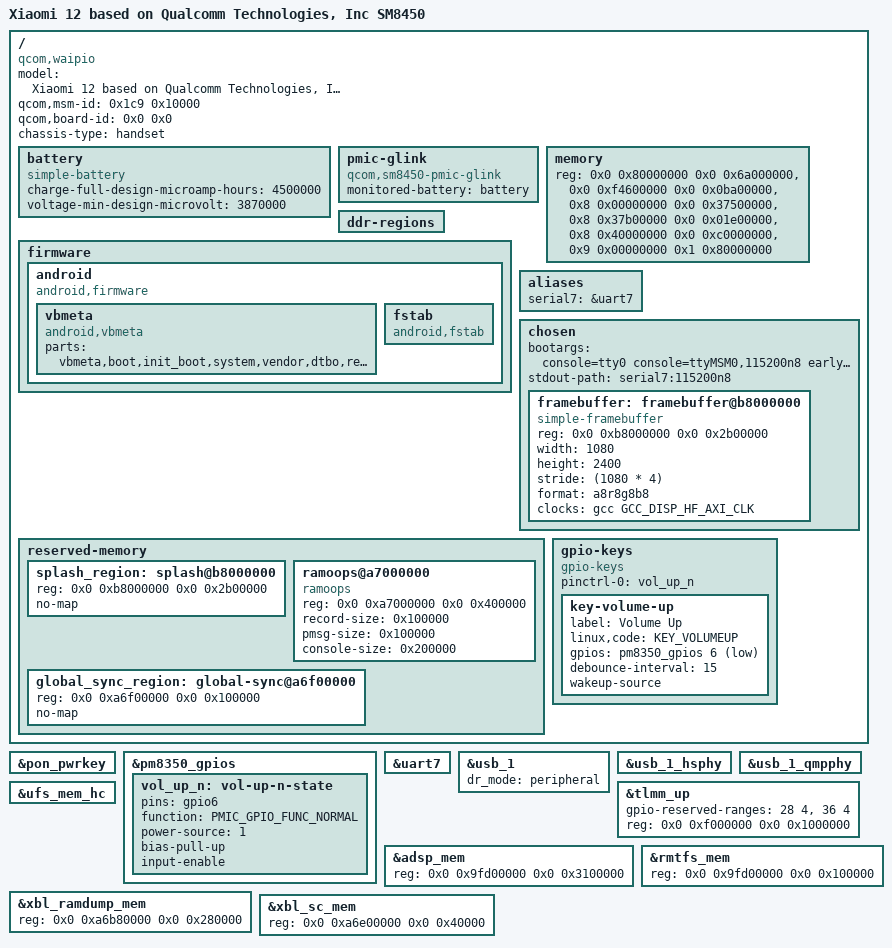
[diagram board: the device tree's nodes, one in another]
// SPDX-License-Identifier: GPL-2.0-only
/*
 * Board device tree for Xiaomi 12 (cupid) — Qualcomm SM8450 (Snapdragon 8 Gen 1).
 *
 * All values from on-device forensics (2026-10-27):
 *   - runtime device tree (private/device-tree.tar, kernel 5.10.237 vendor build)
 *   - /proc/cmdline, fastboot getvar all, panel modes
 * Reference template: sm8475-xiaomi-marble.dts (same-generation Xiaomi port).
 *
 * Minimal boot set (android-mainline-port step 3): console, USB device mode,
 * UFS, keys, ramoops, borrowed firmware framebuffer. Peripherals (panel
 * native takeover, touch, audio, Wi-Fi) follow in later steps.
 */
/dts-v1/;

#include <dt-bindings/arm/qcom,ids.h>
#include <dt-bindings/gpio/gpio.h>
#include <dt-bindings/input/input.h>
#include <dt-bindings/pinctrl/qcom,pmic-gpio.h>
#include <dt-bindings/regulator/qcom,rpmh-regulator.h>

#include "sm8450.dtsi"
#include "pm8350.dtsi"
#include "pm8350b.dtsi"
#include "pm8350c.dtsi"
#include "pm8450.dtsi"
#include "pmk8350.dtsi"
#include "pmr735a.dtsi"
#include "sm8450-xiaomi-cupid-syms.dtsi"

/*
 * XBL allocates firmware carve-outs per device. The SoC dtsi placeholders
 * for adsp/xbl_ramdump/xbl_sc do not match this unit (forensics:
 * adsp@9fd00000, xbl_ramdump@a6b80000, xbl-sc@a6e00000) and are overridden
 * by label at the end of this file. mpss_mem@8bc00000 already matches.
 */

/ {
	model = "Xiaomi 12 based on Qualcomm Technologies, Inc SM8450";
	compatible = "qcom,waipio", "xiaomi,cupid", "qcom,sm8450";
	/*
	 * ABL picks the matching DTB out of the vendor_boot multi-DTB
	 * container by qcom,msm-id + qcom,board-id.
	 *
	 * SM8450 is Waipio: the stock container's waipio entry carries
	 * msm-id <0x1c9 0x10000>, board-id <0 0>. (Entry 0 of the same
	 * container is cape-v2 = SM8475, a different SoC — do not copy it.)
	 * The values in the runtime /sys/firmware/fdt (<201 0 226 0>) are
	 * what the dtbo overlay wrote over the root afterwards.
	 */
	qcom,msm-id = <0x1c9 0x10000>;
	qcom,board-id = <0x0 0x0>;
	chassis-type = "handset";

	/*
	 * Battery/charger run in ADSP firmware (battmgr) over pmic_glink.
	 * 4500 mAh cell (spec); design voltage assumed — verify on device.
	 */
	battery: battery {
		compatible = "simple-battery";
		charge-full-design-microamp-hours = <4500000>;
		voltage-min-design-microvolt = <3870000>;
	};

	pmic-glink {
		compatible = "qcom,sm8450-pmic-glink", "qcom,pmic-glink";
		#address-cells = <1>;
		#size-cells = <0>;
		monitored-battery = <&battery>;
	};

	/delete-node/ memory@a0000000;

	/*
	 * 12 GiB LPDDR5, six physical banks from the runtime DT + Android
	 * /proc/iomem System RAM. The stock base DTB leaves /memory empty for
	 * ABL to fill, but ABL does not fill OUR tree (it only patches the
	 * shape it shipped) — leaving reg empty here means the kernel starts
	 * with zero memory and panics before it can print anything.
	 */
	memory {
		device_type = "memory";
		reg = <0x0 0x80000000 0x0 0x6a000000>,
		      <0x0 0xf4600000 0x0 0x0ba00000>,
		      <0x8 0x00000000 0x0 0x37500000>,
		      <0x8 0x37b00000 0x0 0x01e00000>,
		      <0x8 0x40000000 0x0 0xc0000000>,
		      <0x9 0x00000000 0x1 0x80000000>;
	};

	ddr-regions {
	};

	/* Stock base DTB carries these; keep the same shape for the ABL. */
	firmware {
		android {
			compatible = "android,firmware";

			vbmeta {
				compatible = "android,vbmeta";
				parts = "vbmeta,boot,init_boot,system,vendor,dtbo,recovery";
			};

			fstab {
				compatible = "android,fstab";
			};
		};
	};

	aliases {
		serial7 = &uart7;
	};

	chosen {
		/*
		 * ABL reads /chosen/bootargs from the device tree (not just the
		 * boot.img header) and appends its own args. Keep it short — the
		 * bootloader's buffer is ~512 bytes and silently truncates.
		 */
		bootargs = "console=tty0 console=ttyMSM0,115200n8 earlycon loglevel=8 ignore_loglevel panic=10";
		stdout-path = "serial7:115200n8";

		/*
		 * Borrowed firmware display (splash_region, forensics: 0xb8000000
		 * 43 MiB, 1080x2400). First-boot only; native takeover in step 4.
		 * Panel: qcom,mdss_dsi_l3_42_02_0a_dsc_cmd (SeeYA OLED).
		 */
		framebuffer: framebuffer@b8000000 {
			compatible = "simple-framebuffer";
			reg = <0x0 0xb8000000 0x0 0x2b00000>;
			width = <1080>;
			height = <2400>;
			stride = <(1080 * 4)>;
			format = "a8r8g8b8";
			/* keep the display AXI clock alive — without it writes to
			 * the borrowed framebuffer do not reach the panel */
			clocks = <&gcc GCC_DISP_HF_AXI_CLK>;
		};
	};

	reserved-memory {
		splash_region: splash@b8000000 {
			reg = <0x0 0xb8000000 0x0 0x2b00000>;
			no-map;
		};

		ramoops@a7000000 {
			compatible = "ramoops";
			reg = <0x0 0xa7000000 0x0 0x400000>;
			record-size = <0x100000>;
			pmsg-size = <0x100000>;
			console-size = <0x200000>;
		};

		global_sync_region: global-sync@a6f00000 {
			reg = <0x0 0xa6f00000 0x0 0x100000>;
			no-map;
		};

		/* TODO(step 6 remotes): slpi@88000000/cdsp@89900000 placeholders
		 * already match this unit; add adsp_heap/audio_cma/spss/spu/va_md/
		 * camera/video/cvp/demura when those subsystems are enabled. */
	};

	gpio-keys {
		compatible = "gpio-keys";
		pinctrl-0 = <&vol_up_n>;
		pinctrl-names = "default";

		key-volume-up {
			label = "Volume Up";
			linux,code = <KEY_VOLUMEUP>;
			/* forensics: pm8350@1 pinctrl key_vol_up; gpio6 per
			 * marble reference — verify pins in key_vol_up_default */
			gpios = <&pm8350_gpios 6 GPIO_ACTIVE_LOW>;
			debounce-interval = <15>;
			wakeup-source;
		};
	};
};

&pon_pwrkey {
	status = "okay";
};

&pm8350_gpios {
	vol_up_n: vol-up-n-state {
		pins = "gpio6";
		function = PMIC_GPIO_FUNC_NORMAL;
		power-source = <1>;
		bias-pull-up;
		input-enable;
	};
};

&uart7 {
	status = "okay";
};

&usb_1 {
	status = "okay";
	/* netboot phase: device mode for USB NCM debug link.
	 * sm8450.dtsi merges the dwc3 core into usb_1 itself. */
	dr_mode = "peripheral";
};

/* Both PHYs are disabled in sm8450.dtsi — without them the dwc3
 * controller defers forever and no UDC appears for the gadget. */
&usb_1_hsphy {
	status = "okay";
};

&usb_1_qmpphy {
	status = "okay";
};

&ufs_mem_hc {
	status = "okay";
};

/*
 * GPIO 28-31 / 36-39 belong to TrustZone (stock waipio DTB:
 * qcom,gpios-reserved = <0x1c 0x1d 0x1e 0x1f 0x24 0x25 0x26 0x27>).
 * Without gpio-reserved-ranges the pinctrl driver touches their
 * registers during probe -> XPU violation -> SoC hang + watchdog reset
 * (same failure mode as Xiaomi 13/fuxi, see fuxi-linux notes).
 */
&tlmm_up {
	gpio-reserved-ranges = <28 4>, <36 4>;
};

/* XBL firmware carve-outs, on-device values (forensics) */
&adsp_mem {
	reg = <0x0 0x9fd00000 0x0 0x3100000>;
};

&rmtfs_mem {
	/* No standalone rmtfs on this unit; the dtsi placeholder address
	 * (0x9fd00000) is the ADSP region here. Shrink inside the ADSP
	 * reservation — harmless overlap, revisited when MSS is enabled. */
	reg = <0x0 0x9fd00000 0x0 0x100000>;
};

&xbl_ramdump_mem {
	reg = <0x0 0xa6b80000 0x0 0x280000>;
};

&xbl_sc_mem {
	reg = <0x0 0xa6e00000 0x0 0x40000>;
};


/*
 * Test B: this unit is first-batch waipio silicon whose TLMM config space
 * sits at 0xf000000 (stock base DTB: reg = <0xf000000 0x1000000>), while
 * mainline sm8450.dtsi assumes 0xf100000 (later SM8450 steppings). Reading
 * 0xf100000-based offsets hits the XPU-protected region past gpio211 ->
 * SoC hang during pinctrl probe.
 */
&tlmm_up {
	reg = <0x0 0xf000000 0x0 0x1000000>;
};
